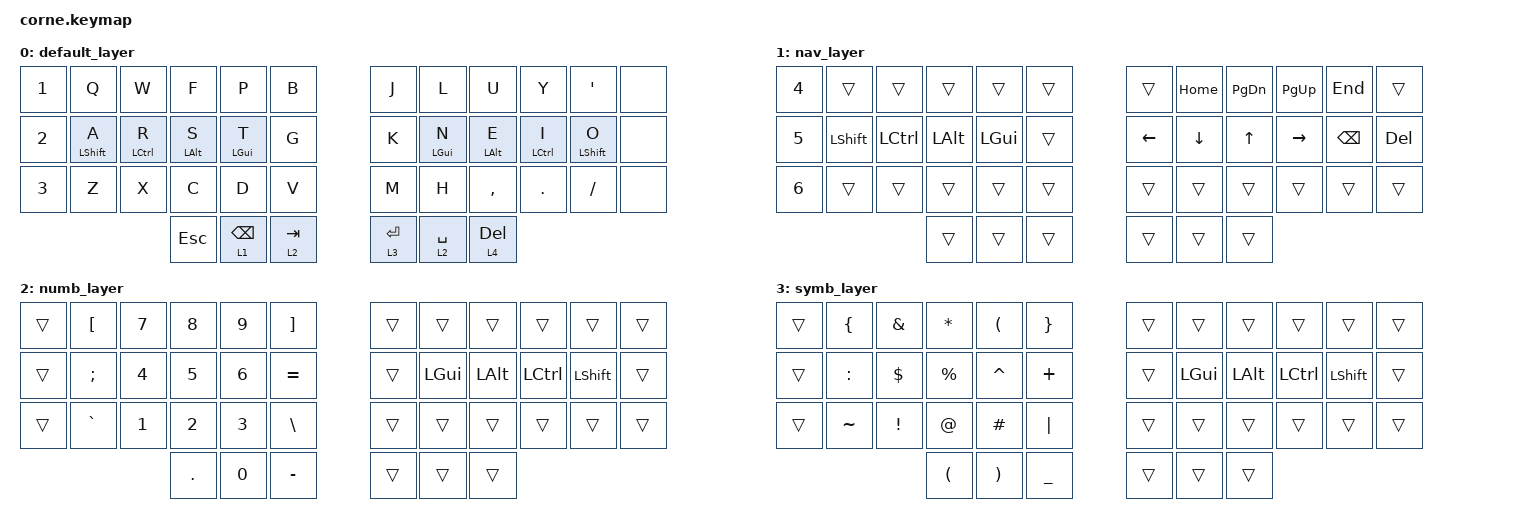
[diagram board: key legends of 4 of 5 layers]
/*
 * Copyright (c) 2020 The ZMK Contributors
 *
 * SPDX-License-Identifier: MIT
*/

#include <behaviors.dtsi>
#include <dt-bindings/zmk/keys.h>
#include <dt-bindings/zmk/bt.h>

/ {
        behavior {
            bhm: balanced_homerow_mods {
                compatible = "zmk,behavior-hold-tap";
                label = "HOMEROW_MODS";
                #binding-cells = <2>;
                tapping-term-ms = <179>;
                quick-tap-ms = <0>;
                flavor = "balanced";
                bindings = <&kp>, <&kp>;
            };
        };
        keymap {
                compatible = "zmk,keymap";

                default_layer {
// -----------------------------------------------------------------------------------------
// |  TAB |  Q  |  W  |  E  |  R  |  T  |   |  Y  |  U   |  I  |  O  |  P  | BKSP |
// | CTRL |  A  |  S  |  D  |  F  |  G  |   |  H  |  J   |  K  |  L  |  ;  |  '   |
// | SHFT |  Z  |  X  |  C  |  V  |  B  |   |  N  |  M   |  ,  |  .  |  /  | ESC  |
//                    | ESC | LWR | SPC |   | ENT | RSE  | ALT |
                        bindings = <
   &kp N1   &kp Q            &kp W           &kp F           &kp P           &kp B       /**/    &kp J       &kp L           &kp U           &kp Y           &kp SQT         &none
   &kp N2   &bhm LSHIFT A    &bhm LCTRL R    &bhm LALT S     &bhm LGUI T     &kp G       /**/    &kp K       &bhm LGUI N     &bhm LALT E     &bhm LCTRL I    &bhm LSHIFT O   &none
   &kp N3   &kp Z            &kp X           &kp C           &kp D           &kp V       /**/    &kp M       &kp H           &kp COMMA       &kp DOT         &kp FSLH        &none
                                          &kp ESC         &lt 1 BSPC      &lt 2 TAB   /**/    &lt 3 RET   &lt 2 SPACE     &lt 4 DEL
                        >;
                };
                nav_layer {
// -----------------------------------------------------------------------------------------
// |  TAB |  1  |  2  |  3  |  4  |  5  |   |  6  |  7  |  8  |  9  |  0  | BKSP |
// | BTCLR| BT1 | BT2 | BT3 | BT4 | BT5 |   | LFT | DWN |  UP | RGT |     |      |
// | SHFT |     |     |     |     |     |   |     |     |     |     |     |      |
//                    |    |     | SPC |   | ENT |     | ALT |
                        bindings = <
   &kp N4   &trans      &trans      &trans      &trans      &trans   /**/  &trans      &kp HOME    &kp PG_DN   &kp PG_UP   &kp END      &trans
   &kp N5   &kp LSHIFT  &kp LCTRL   &kp LALT    &kp LGUI    &trans   /**/  &kp LEFT    &kp DOWN    &kp UP      &kp RIGHT   &kp BSPC     &kp DEL
   &kp N6   &trans      &trans      &trans      &trans      &trans   /**/  &trans      &trans      &trans      &trans      &trans       &trans
                          	        &trans      &trans      &trans   /**/  &trans      &trans      &trans
                        >;
                };
                numb_layer {
// -----------------------------------------------------------------------------------------
// |  TAB |  !  |  @  |  #  |  $  |  %  |   |  ^  |  &  |  *  |  (  |  )  | BKSP |
// | CTRL |     |     |     |     |     |   |  -  |  =  |  [  |  ]  |  \  |  `   |
// | SHFT |     |     |     |     |     |   |  _  |  +  |  {  |  }  | "|" |  ~   |
//                    | GUI |     | SPC |   | ENT |     | ALT |
                        bindings = <
   &trans   &kp LBKT    &kp N7   &kp N8   &kp N9   &kp RBKT   /**/   &trans      &trans     &trans      &trans      &trans      &trans
   &trans   &kp SEMI    &kp N4   &kp N5   &kp N6   &kp EQUAL  /**/   &trans      &kp LGUI   &kp LALT    &kp LCTRL   &kp LSHIFT     &trans
   &trans   &kp GRAVE   &kp N1   &kp N2   &kp N3   &kp BSLH   /**/   &trans      &trans     &trans      &trans      &trans      &trans
                                 &kp DOT  &kp N0   &kp MINUS  /**/   &trans      &trans     &trans
                        >;
                };
                symb_layer {
// -----------------------------------------------------------------------------------------
// |  TAB |  !  |  @  |  #  |  $  |  %  |   |  ^  |  &  |  *  |  (  |  )  | BKSP |
// | CTRL |     |     |     |     |     |   |  -  |  =  |  [  |  ]  |  \  |  `   |
// | SHFT |     |     |     |     |     |   |  _  |  +  |  {  |  }  | "|" |  ~   |
//                    | GUI |     | SPC |   | ENT |     | ALT |
                        bindings = <
   &trans   &kp LBRC    &kp AMPS    &kp STAR    &kp LPAR    &kp RBRC    /**/  &trans   &trans       &trans      &trans      &trans        &trans
   &trans   &kp COLON   &kp DLLR    &kp PRCNT   &kp CARET   &kp PLUS    /**/  &trans   &kp LGUI     &kp LALT    &kp LCTRL   &kp LSHIFT    &trans
   &trans   &kp TILDE   &kp EXCL    &kp AT      &kp POUND   &kp PIPE    /**/  &trans   &trans       &trans      &trans      &trans        &trans
                                    &kp LPAR    &kp RPAR    &kp UNDER   /**/  &trans   &trans       &trans
                        >;
                };
                fs_layer {
// -----------------------------------------------------------------------------------------
// |  TAB |  !  |  @  |  #  |  $  |  %  |   |  ^  |  &  |  *  |  (  |  )  | BKSP |
// | CTRL |     |     |     |     |     |   |  -  |  =  |  [  |  ]  |  \  |  `   |
// | SHFT |     |     |     |     |     |   |  _  |  +  |  {  |  }  | "|" |  ~   |
//                    | GUI |     | SPC |   | ENT |     | ALT |
                        bindings = <
   &trans   &kp F12   &kp F7  &kp F8   &kp F9   &trans   /**/  &trans   &bt BT_SEL 0    &bt BT_SEL 1    &bt BT_SEL 2    &bt BT_SEL 3      &bt BT_CLR
   &trans   &kp F11   &kp F4  &kp F5   &kp F6   &trans   /**/  &trans   &trans          &kp LGUI     &kp LALT    &kp LCTRL   &kp LSHIFT   &trans
   &trans   &kp F10   &kp F1  &kp F12  &kp F3   &trans   /**/  &trans   &trans          &trans          &trans          &trans            &trans
                              &trans   &trans   &trans   /**/  &trans   &trans          &trans
                        >;
                };
        };
};
